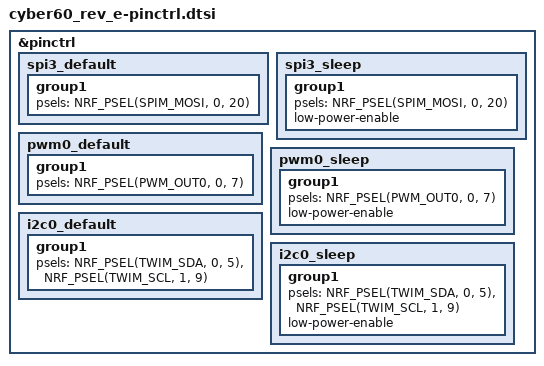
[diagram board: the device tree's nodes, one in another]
/*
 * Copyright (c) 2022 The ZMK Contributors
 * SPDX-License-Identifier: MIT
 */


&pinctrl {
    spi3_default: spi3_default {
        group1 {
            psels = <NRF_PSEL(SPIM_MOSI, 0, 20)>; // P0,20 underglow pin
        };
    };
    spi3_sleep: spi3_sleep {
        group1 {
            psels = <NRF_PSEL(SPIM_MOSI, 0, 20)>;
            low-power-enable;
        };
    };

    pwm0_default: pwm0_default {
        group1 {
            psels = <NRF_PSEL(PWM_OUT0, 0, 7)>; // P0,27 buzzer pin
        };
    };
    pwm0_sleep: pwm0_sleep {
        group1 {
            psels = <NRF_PSEL(PWM_OUT0, 0, 7)>;
            low-power-enable;
        };
    };

    i2c0_default: i2c0_default {
        group1 {
            psels = <NRF_PSEL(TWIM_SDA, 0, 5)>,   // P0.5 SDA
                    <NRF_PSEL(TWIM_SCL, 1, 9)>;  // P1.9 SCL
        };
    };

    i2c0_sleep: i2c0_sleep {
        group1 {
            psels = <NRF_PSEL(TWIM_SDA, 0, 5)>,
                    <NRF_PSEL(TWIM_SCL, 1, 9)>;
            low-power-enable;
        };
    }; 
};
